# K1921VG1T register map
Vendor: NIIET; Series: K1921VGx; File version: 2.8
CPU: other r0p1, little endian, MPU, FPU, 4 interrupt priority bits
Registers are 32-bit, read-write, reset 0x0 unless marked. A register's access mark holds for its fields unless they carry their own. Offsets are from the block's base; [hi:lo] are bit positions; lines under a group give offsets from that group; {n}, {i} and the like mark numbered series.

## CANFD0 — CANFD control registers
Base 0x41000000
Same registers: CANFD1 0x41001000, CANFD2 0x41002000, CANFD3 0x41003000
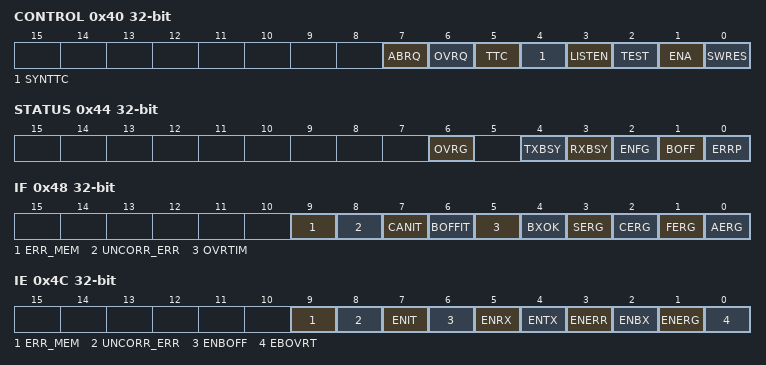
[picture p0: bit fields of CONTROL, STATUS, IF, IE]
0x40 CONTROL — CAN General Control Register
  [7] ABRQ — Break request
  [6] OVRQ — Request for overrun frame
  [5] TTC — TTC Mode Enable
  [4] SYNTTC — TTC Capture Mode
    0=CAP_SOF (Capture TTC Timer by SOF bit); 1=CAP_EOF (Capture TTC Timer by EOF bit)
  [3] LISTEN — Listen Mode
  [2] TEST — Test mode (not used)
  [1] ENA — Enable CAN Channel
  [0] SWRES — Software Reset and Reset Status
0x44 STATUS ro — CAN General Status Register
  [6] OVRG — CAN Timer Overrun Interrupt
  [4] TXBSY — Transmitter Busy Flag
  [3] RXBSY — Receiver Busy Flag
  [2] ENFG — Enable Flag
  [1] BOFF — CAN Bus Disable Flag
  [0] ERRP — Passive mode error
0x48 IF — CAN General Interrupt Register
  [9] ERR_MEM — Single Error when reading a memory
  [8] UNCORR_ERR — Double Error while reading a memory
  [7] CANIT ro — Common Interrupt Flag
  [6] BOFFIT — Interrupt due to Bus Disable
  [5] OVRTIM — CAN Timer Overrun Interrupt
  [4] BXOK — Frame Buffer Receive Interrupt
  [3] SERG — Common Error Interrupt
  [2] CERG — CRC Error Interrupt
  [1] FERG — Frame Error Interrupt
  [0] AERG — Acknowledge Error Interrupt
0x4C IE — CAN General Interrupt Enable Register
  [9] ERR_MEM — Enable interrupt when single error detected
  [8] UNCORR_ERR — Enable interrupt when double error detected
  [7] ENIT — Enable All Interrupts
  [6] ENBOFF — Enable Bus Disable Interrupt
  [5] ENRX — Receive Interrupt Enable
  [4] ENTX — Transmit Interrupt Enable
  [3] ENERR — Enable MOb Error Interrupts
  [2] ENBX
  [1] ENERG — Enable Error Interrupt
  [0] EBOVRT — Enable CAN Timer Overrun Interrupt
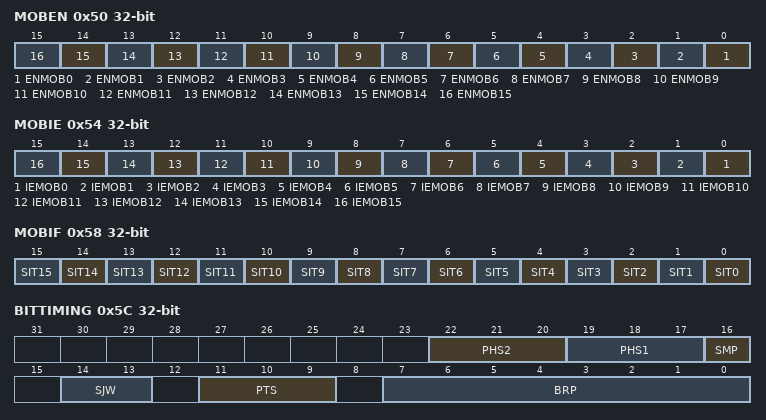
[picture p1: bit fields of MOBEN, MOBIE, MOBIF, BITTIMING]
0x50 MOBEN ro — CAN Enable MOb Register
  [n] ENMOB{n} (n=0..15) — Message Object {n} is Enabled
0x54 MOBIE — CAN Enable Interrupt MOb Register
  [n] IEMOB{n} (n=0..15) — Message Object {n} Interrupt Enable
0x58 MOBIF ro — CAN Status Interrupt MOb Register
  [n] SIT{n} (n=0..15) — Interrupt Status {n}
0x5C BITTIMING — CAN Bit Timing Register
  [22:20] PHS2 — Phase Segment 2
  [19:17] PHS1 — Phase Segment 1
  [16] SMP — Sample Point
  [14:13] SJW — Synchronization Jump Width
  [11:9] PTS — Propagation Time Segment
  [7:0] BRP — Baud Rate
0x60 TIMERCTRL — CAN Timer Control Register
  [7:0] TPRSC — Timer Prescale
0x64 TIMERVAL ro — CAN Timer Register
  [15:0] CANTIM — CAN Timer Value
0x68 TTCVAL ro — CAN TTC Timer Register
  [15:0] TIMTTC — CAN TTC Timer Value
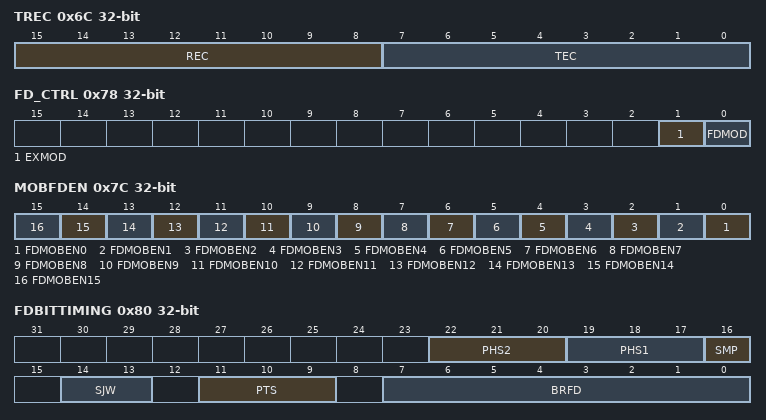
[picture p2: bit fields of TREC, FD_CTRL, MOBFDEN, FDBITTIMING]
0x6C TREC ro — CAN Transmit Error Counter Register
  [15:8] REC — Receive Error Counter Value
  [7:0] TEC — Transmit Error Counter Value
0x70 HPRIMOB reset 0x1F0 — CAN Highest Priority MOb Register
  [8:4] HPMOB — Highest Priority MOb Number
0x78 FD_CTRL — CAN FD Mode Register
  [1] EXMOD — CAN FD ISO Select
    0=NONISO (In CAN FD mode create packet in non-ISO format); 1=ISO (In CAN FD mode create packet in ISO format)
  [0] FDMOD — Enable CAN FD Mode
    0=CAN20 (Can 2.0 Mode); 1=CANFD (CAN FD Mode)
0x7C MOBFDEN — CAN MOb FD Mode Enable Register
  [n] FDMOBEN{n} (n=0..15) — Message Object {n} FD Mode Enable
0x80 FDBITTIMING — CAN FD Bit Timing Register
  [22:20] PHS2 — Phase Segment 2
  [19:17] PHS1 — Phase Segment 1
  [16] SMP — Sample Point
  [14:13] SJW — Synchronization Jump Width
  [11:9] PTS — Propagation Time Segment
  [7:0] BRFD — Baud Rate in FD Mode
0xA8 MOBPAGE — CAN Page MOb Register
  [4:0] MOBNB — Message Object Number
0xAC TIMESTAMP ro — CAN Timestamp Register
  [15:0] TIMSTM — Timestamp Counter Value
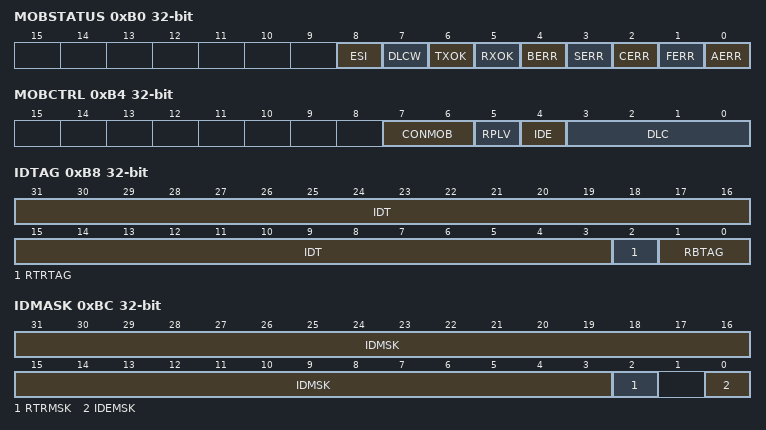
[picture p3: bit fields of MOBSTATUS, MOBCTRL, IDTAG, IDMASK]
0xB0 MOBSTATUS — CAN MOb Status Register
  [8] ESI — Error State Indicator flag
    0=ERROR_ACTIVE (A CANFD frame was transmitted by node in the Error Active state. Or a CAN2.0 frame was transmitted); 1=ERROR_PASSIVE (A CANFD frame was transmitted by node in the Error Passive state)
  [7] DLCW — Data Length Code Warning
  [6] TXOK — Transmit OK
  [5] RXOK — Receive OK
  [4] BERR — Bit Error while Transmit
  [3] SERR — Serial Error
  [2] CERR — CRC Error Interrupt
  [1] FERR — Frame Error Interrupt
  [0] AERR — Acknowledge Error Interrupt
0xB4 MOBCTRL — CAN MOb Control and DLC Register
  [7:6] CONMOB — MOb Configuration
  [5] RPLV — Reply Active
  [4] IDE — Identificator Extension
  [3:0] DLC — Data Length Code
0xB8 IDTAG — CAN Identifier Tag Register
  [31:3] IDT — Identification Tag
  [2] RTRTAG — Remote Transmit Tag
  [1:0] RBTAG — RB Tag of Remote Device
0xBC IDMASK — CAN Identifier Mask Register
  [31:3] IDMSK — Identificator Mask
  [2] RTRMSK — Remote Transmite Mask
  [0] IDEMSK — Extended Identificator Mask
{0xC0+4i} MESSAGE[{i}] (i=0..15) group
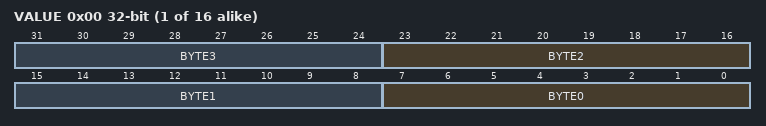
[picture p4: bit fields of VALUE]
  0x00 VALUE — CAN Data Message Register
    [8n+7:8n] BYTE{n} (n=0..3) — Message Value (byte {n})
